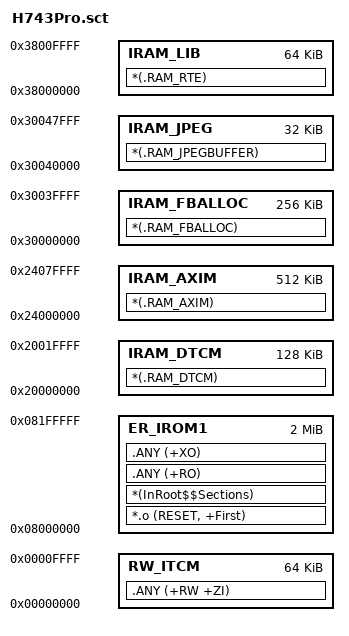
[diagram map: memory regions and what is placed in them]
; *************************************************************
; *** Scatter-Loading Description File generated by uVision ***
; *************************************************************

LR_IROM1 0x08000000 0x00200000  {    ; load region size_region
  ER_IROM1 0x08000000 0x00200000  {  ; load address = execution address
   *.o (RESET, +First)
   *(InRoot$$Sections)
   .ANY (+RO)
   .ANY (+XO)
  }
  RW_ITCM 0x00000000 0x00010000  {  ; TCM RAM（400MHz）ITCM 128K 用于MDK管理 不可以被DMA访问
   .ANY (+RW +ZI)
  }
  IRAM_DTCM 0x20000000 0X00020000 {  ; TCM RAM（400MHz）DTCM 128K 用于MV库运算 不可以被DMA访问
   *(.RAM_DTCM)
  }
  IRAM_AXIM 0x24000000 0x00080000 {  ; AXI SRAM（200MHz） 512K 用于图像缓存
   *(.RAM_AXIM)
  }
  
  IRAM_FBALLOC 0x30000000 0X00040000 {  ; SRAM1+SRAM2 256K AHB SRAM（D2域，200MHz） 用于FB_ALLOC
   *(.RAM_FBALLOC)
  }
  
  IRAM_JPEG 0x30040000 0X00008000 {  ;  AHB SRAM（D2域，200MHz）SRAM3 32K 用于JPEG缓存
   *(.RAM_JPEGBUFFER)
  }
  
  IRAM_LIB 0x38000000 0X00010000 {  ;  AHB RAM（D3域，200MHz）SRAM4 64K 用于RTE内存管理
   *(.RAM_RTE)
  }
  
}

